VERSION ""

NS_ :

BS_:

BU_: Implement
VAL_TABLE_ Fault_Sig 1 "Fault" 0 "OK" ;
VAL_TABLE_ operation_mode 6 "Stop mode 2" 5 "Stop mode 1" 4 "Limited mode 4" 3 "Limited mode 3" 2 "Limited mode 2" 1 "Limited mode 1 " 0 "Normal Operation" ;

BO_ 3221225472 VECTOR__INDEPENDENT_SIG_MSG: 0 Vector__XXX
 SG_ New_Signal_80 : 0|8@1+ (1,0) [0|0] "" Vector__XXX
 SG_ New_Signal_78 : 0|8@1+ (1,0) [0|0] "" Vector__XXX
 SG_ _Bus_Input_Port_OutFaults : 0|16@0+ (1,0) [0|0] "" Vector__XXX
 SG_ MtrRpmFltrdDelay : 0|16@0- (1,0) [0|0] "" Vector__XXX
 SG_ MtrCrntFltrdDelay : 0|16@0- (1,0) [0|0] "" Vector__XXX
 SG_ Motor_rpm_sum : 0|16@0+ (1,0) [0|0] "RPM" Vector__XXX
 SG_ Cal_seq : 0|8@0+ (1,0) [0|0] "" Vector__XXX
 SG_ MtrRpmFltrdDelay : 0|16@0- (1,0) [0|0] "" Vector__XXX
 SG_ _Bus_Diag_Port_OD_MtrRpmFltrd : 0|16@0- (1,0) [0|0] "" Vector__XXX
 SG_ Operation_Mode : 0|8@0+ (1,0) [0|0] "" Vector__XXX
 SG_ MxDispRpmCapt : 0|16@0+ (1,0) [0|0] "" Vector__XXX
 SG_ _Bus_Diag_Port_OD_MtrFbCrntFltrd : 0|16@0- (1,0) [0|0] "" Vector__XXX
 SG_ TankLevel : 0|16@1+ (1,0) [0|10600] "L" Vector__XXX

BO_ 568 _Bus_Outputs_Braking_Abnormal: 8 Vector__XXX
 SG_ Press_Sensor_Plaus_Check : 15|8@0+ (1,0) [0|0] "" Vector__XXX
 SG_ Braking_Abnormal : 0|8@1+ (1,0) [0|0] "" Vector__XXX

BO_ 569 DanfossVersion: 8 Vector__XXX
 SG_ DanfossModuleVersion : 39|32@0+ (1,0) [0|0] "" Vector__XXX
 SG_ DanfossConfigVersion : 7|32@0+ (1,0) [0|0] "" Vector__XXX

BO_ 567 _Bus_Input_Port_OutFaults: 8 Vector__XXX
 SG_ _Bus_Input_Port_AggrMode_LvrAcc : 24|8@1- (1,0) [0|0] "" Vector__XXX
 SG_ _Bus_Input_Port_OperationMode : 23|8@0+ (1,0) [0|0] "" Vector__XXX
 SG_ PmpRvs_short_to_battery : 9|1@0+ (1,0) [0|0] "" Vector__XXX
 SG_ PmpFwd_short_to_battery : 8|1@0+ (1,0) [0|0] "" Vector__XXX
 SG_ ParkBrake_short_to_battery : 15|1@0+ (1,0) [0|0] "" Vector__XXX
 SG_ MtrCoilRR_coil_short_to_battery : 13|1@0+ (1,0) [0|0] "" Vector__XXX
 SG_ MtrCoilRL_coil_short_to_battery : 12|1@0+ (1,0) [0|0] "" Vector__XXX
 SG_ MtrCoilFR_coil_short_to_battery : 11|1@0+ (1,0) [0|0] "" Vector__XXX
 SG_ MtrCoilFL_coil_short_to_battery : 10|1@0+ (1,0) [0|0] "" Vector__XXX
 SG_ CCO_short_to_battery : 14|1@0+ (1,0) [0|0] "" Vector__XXX
 SG_ PmpRvs_coil_open_short_to_GND : 1|1@0+ (1,0) [0|0] "" Vector__XXX
 SG_ PmpFwd_coil_open_short_to_GND : 0|1@0+ (1,0) [0|0] "" Vector__XXX
 SG_ ParkBrake_open_short_to_GND : 7|1@0+ (1,0) [0|0] "" Vector__XXX
 SG_ MtrCoilRR_coil_open_short_to_GND : 5|1@0+ (1,0) [0|0] "" Vector__XXX
 SG_ MtrCoilRL_coil_open_short_to_GND : 4|1@0+ (1,0) [0|0] "" Vector__XXX
 SG_ MtrCoilFR_coil_open_short_to_GND : 3|1@0+ (1,0) [0|0] "" Vector__XXX
 SG_ MtrCoilFL_coil_open_short_to_GND : 2|1@0+ (1,0) [0|0] "" Vector__XXX
 SG_ CCO_open_short_to_GND : 6|1@0+ (1,0) [0|0] "" Vector__XXX

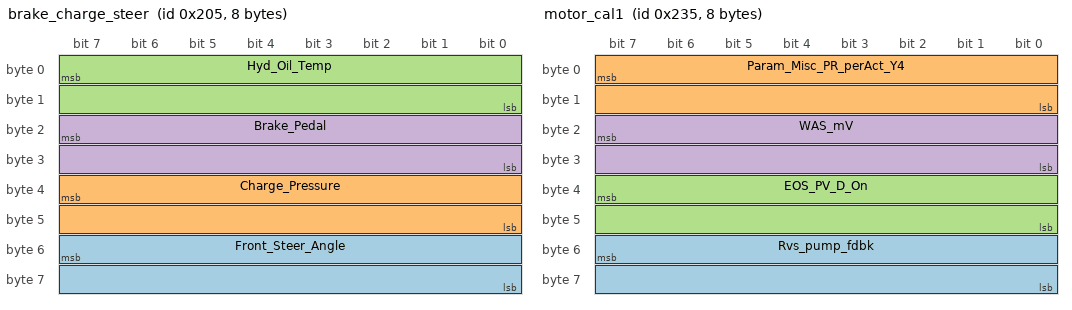
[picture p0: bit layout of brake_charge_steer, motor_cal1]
BO_ 517 brake_charge_steer: 8 Vector__XXX
 SG_ Front_Steer_Angle : 55|16@0- (0.01,0) [0|0] "deg" Vector__XXX
 SG_ Charge_Pressure : 39|16@0+ (1,0) [0|0] "" Vector__XXX
 SG_ Hyd_Oil_Temp : 7|16@0+ (1,0) [0|0] "c" Vector__XXX
 SG_ Brake_Pedal : 23|16@0+ (1,0) [0|0] "%" Vector__XXX

BO_ 565 motor_cal1: 8 Vector__XXX
 SG_ Rvs_pump_fdbk : 55|16@0+ (1,0) [0|0] "mA" Vector__XXX
 SG_ Param_Misc_PR_perAct_Y4 : 7|16@0+ (1,0) [0|0] "" Vector__XXX
 SG_ EOS_PV_D_On : 39|16@0+ (1,0) [0|0] "" Vector__XXX
 SG_ WAS_mV : 23|16@0+ (1,0) [0|0] "mV" Vector__XXX

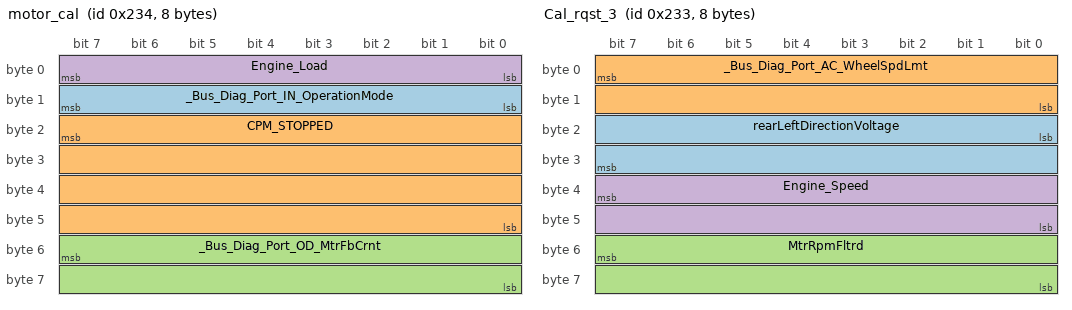
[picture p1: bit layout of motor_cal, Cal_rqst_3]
BO_ 564 motor_cal: 8 Vector__XXX
 SG_ _Bus_Diag_Port_IN_OperationMode : 8|8@1- (1,0) [0|0] "" Vector__XXX
 SG_ CPM_STOPPED : 23|32@0+ (1,0) [0|0] "" Vector__XXX
 SG_ _Bus_Diag_Port_OD_MtrFbCrnt : 55|16@0+ (1,0) [0|0] "" Vector__XXX
 SG_ Engine_Load : 7|8@0+ (1,0) [0|0] "%" Vector__XXX

BO_ 563 Cal_rqst_3: 8 Vector__XXX
 SG_ rearLeftDirectionVoltage : 16|16@1+ (1,0) [0|0] "V" Vector__XXX
 SG_ _Bus_Diag_Port_AC_WheelSpdLmt : 7|16@0+ (1,0) [0|0] "mmSec" Vector__XXX
 SG_ MtrRpmFltrd : 55|16@0- (1,0) [0|0] "" Vector__XXX
 SG_ Engine_Speed : 39|16@0+ (1,0) [0|0] "RPM" Vector__XXX

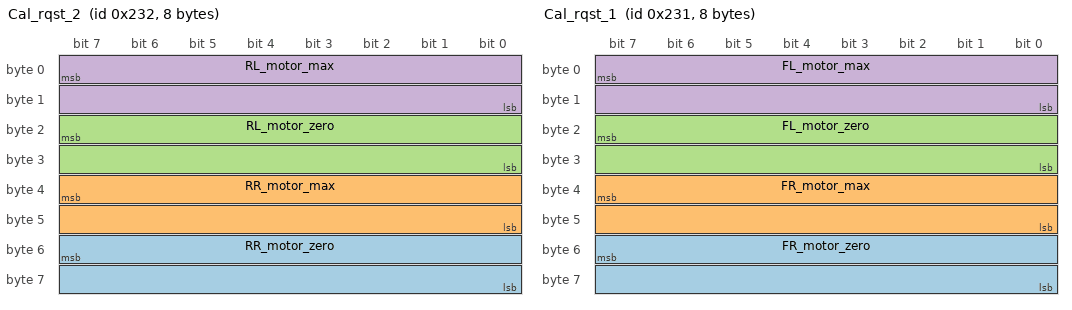
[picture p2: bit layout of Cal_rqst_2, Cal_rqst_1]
BO_ 562 Cal_rqst_2: 8 Vector__XXX
 SG_ RR_motor_zero : 55|16@0+ (1,0) [0|0] "mA" Vector__XXX
 SG_ RR_motor_max : 39|16@0+ (1,0) [0|0] "mA" Vector__XXX
 SG_ RL_motor_zero : 23|16@0+ (1,0) [0|0] "mA" Vector__XXX
 SG_ RL_motor_max : 7|16@0+ (1,0) [0|0] "mA" Vector__XXX

BO_ 561 Cal_rqst_1: 8 Vector__XXX
 SG_ FR_motor_zero : 55|16@0+ (1,0) [0|0] "mA" Vector__XXX
 SG_ FR_motor_max : 39|16@0+ (1,0) [0|0] "mA" Vector__XXX
 SG_ FL_motor_zero : 23|16@0+ (1,0) [0|0] "mA" Vector__XXX
 SG_ FL_motor_max : 7|16@0+ (1,0) [0|0] "mA" Vector__XXX

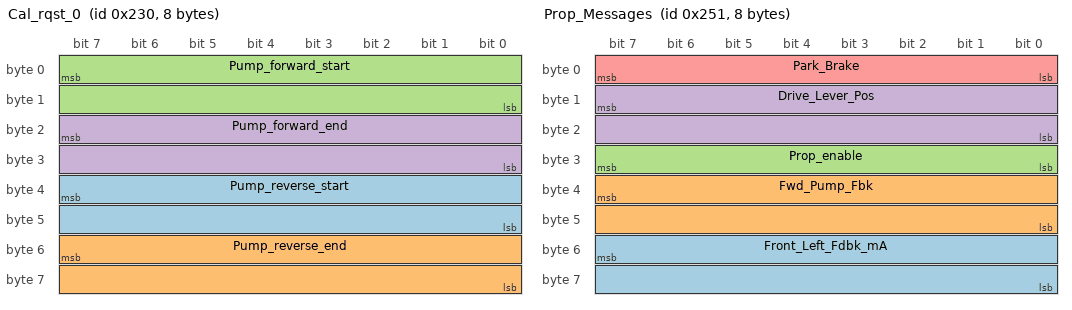
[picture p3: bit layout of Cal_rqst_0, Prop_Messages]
BO_ 560 Cal_rqst_0: 8 Vector__XXX
 SG_ Pump_reverse_start : 39|16@0+ (1,0) [0|0] "mA" Vector__XXX
 SG_ Pump_reverse_end : 55|16@0+ (1,0) [0|0] "mA" Vector__XXX
 SG_ Pump_forward_start : 7|16@0+ (1,0) [0|0] "mA" Vector__XXX
 SG_ Pump_forward_end : 23|16@0+ (1,0) [0|0] "mA" Vector__XXX

BO_ 593 Prop_Messages: 8 Vector__XXX
 SG_ Front_Left_Fdbk_mA : 55|16@0+ (1,0) [0|0] "mA" Vector__XXX
 SG_ Fwd_Pump_Fbk : 39|16@0+ (1,0) [0|0] "mA" Vector__XXX
 SG_ Prop_enable : 24|8@1- (1,0) [0|0] "" Vector__XXX
 SG_ Drive_Lever_Pos : 15|16@0- (1,0) [0|0] "%" Vector__XXX
 SG_ Park_Brake : 0|8@1- (1,0) [0|0] "" Vector__XXX

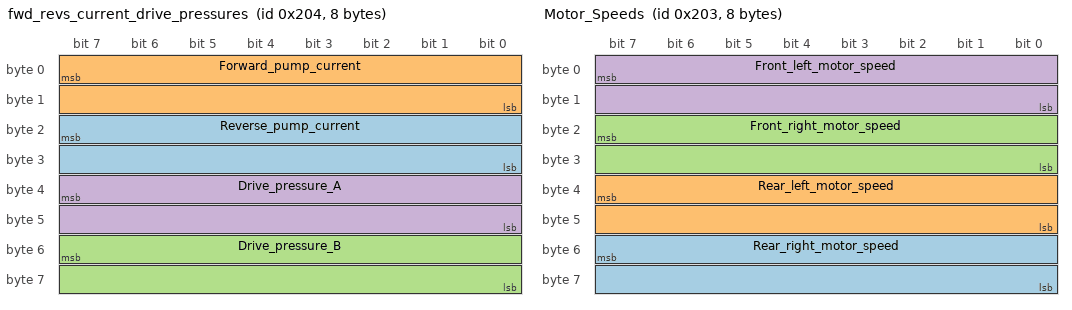
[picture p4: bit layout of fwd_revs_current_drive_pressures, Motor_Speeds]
BO_ 516 fwd_revs_current_drive_pressures: 8 Vector__XXX
 SG_ Reverse_pump_current : 23|16@0+ (1,0) [0|0] "Amps" Vector__XXX
 SG_ Forward_pump_current : 7|16@0+ (1,0) [0|0] "Amps" Vector__XXX
 SG_ Drive_pressure_B : 55|16@0+ (1,0) [0|0] "Bar" Vector__XXX
 SG_ Drive_pressure_A : 39|16@0+ (1,0) [0|0] "Bar" Vector__XXX

BO_ 515 Motor_Speeds: 8 Vector__XXX
 SG_ Rear_right_motor_speed : 55|16@0- (1,0) [0|0] "RPM" Vector__XXX
 SG_ Rear_left_motor_speed : 39|16@0- (1,0) [0|0] "RPM" Vector__XXX
 SG_ Front_right_motor_speed : 23|16@0- (1,0) [0|0] "RPM" Vector__XXX
 SG_ Front_left_motor_speed : 7|16@0- (1,0) [0|0] "RPM" Vector__XXX

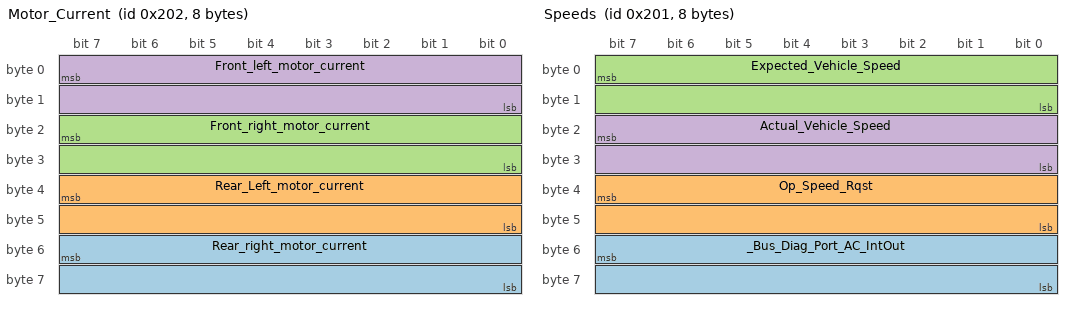
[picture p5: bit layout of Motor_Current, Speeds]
BO_ 514 Motor_Current: 8 Vector__XXX
 SG_ Rear_right_motor_current : 55|16@0+ (1,0) [0|0] "mA" Vector__XXX
 SG_ Rear_Left_motor_current : 39|16@0+ (1,0) [0|0] "mA" Vector__XXX
 SG_ Front_right_motor_current : 23|16@0+ (1,0) [0|0] "mA" Vector__XXX
 SG_ Front_left_motor_current : 7|16@0+ (1,0) [0|0] "mA" Vector__XXX

BO_ 513 Speeds: 8 Vector__XXX
 SG_ _Bus_Diag_Port_AC_IntOut : 55|16@0- (1,0) [0|0] "mm/s" Vector__XXX
 SG_ Op_Speed_Rqst : 39|16@0- (1,0) [0|0] "mm/s" Vector__XXX
 SG_ Expected_Vehicle_Speed : 7|16@0- (1,0) [0|0] "mm/s" Vector__XXX
 SG_ Actual_Vehicle_Speed : 23|16@0- (1,0) [0|0] "mm/s" Vector__XXX

CM_ BO_ 3221225472 "This is a message for not used signals, created by Vector CANdb++ DBC OLE DB Provider.";
BA_DEF_ SG_  "SigType" ENUM  "Default","Range","RangeSigned","ASCII","Discrete","Control","ReferencePGN","DTC","StringDelimiter","StringLength","StringLengthControl","MessageCounter","MessageChecksum";
BA_DEF_ SG_  "GenSigEVName" STRING ;
BA_DEF_ SG_  "GenSigILSupport" ENUM  "No","Yes";
BA_DEF_ SG_  "GenSigSendType" ENUM  "Cyclic","OnWrite","OnWriteWithRepetition","OnChange","OnChangeWithRepetition","IfActive","IfActiveWithRepetition","NoSigSendType";
BA_DEF_ BO_  "GenMsgILSupport" ENUM  "No","Yes";
BA_DEF_ BU_  "NmJ1939SystemInstance" INT 0 15;
BA_DEF_ BU_  "NmJ1939System" INT 0 127;
BA_DEF_ BU_  "NmJ1939ManufacturerCode" INT 0 2047;
BA_DEF_ BU_  "NmJ1939IndustryGroup" INT 0 7;
BA_DEF_ BU_  "NmJ1939IdentityNumber" INT 0 2097151;
BA_DEF_ BU_  "NmJ1939FunctionInstance" INT 0 7;
BA_DEF_ BU_  "NmJ1939Function" INT 0 255;
BA_DEF_ BU_  "NmJ1939ECUInstance" INT 0 3;
BA_DEF_ BU_  "NmJ1939AAC" INT 0 1;
BA_DEF_ BU_  "NmStationAddress" INT 0 255;
BA_DEF_ BO_  "GenMsgSendType" ENUM  "cyclic","NotUsed","IfActive","NotUsed","NotUsed","NotUsed","NotUsed","NotUsed","noMsgSendType";
BA_DEF_ BO_  "GenMsgRequestable" INT 0 1;
BA_DEF_  "DBName" STRING ;
BA_DEF_  "BusType" STRING ;
BA_DEF_  "ProtocolType" STRING ;
BA_DEF_ BO_  "VFrameFormat" ENUM  "StandardCAN","ExtendedCAN","reserved","J1939PG";
BA_DEF_DEF_  "SigType" "Default";
BA_DEF_DEF_  "GenSigEVName" "Env@Nodename_@Signame";
BA_DEF_DEF_  "GenSigILSupport" "Yes";
BA_DEF_DEF_  "GenSigSendType" "NoSigSendType";
BA_DEF_DEF_  "GenMsgILSupport" "Yes";
BA_DEF_DEF_  "NmJ1939SystemInstance" 0;
BA_DEF_DEF_  "NmJ1939System" 0;
BA_DEF_DEF_  "NmJ1939ManufacturerCode" 0;
BA_DEF_DEF_  "NmJ1939IndustryGroup" 0;
BA_DEF_DEF_  "NmJ1939IdentityNumber" 0;
BA_DEF_DEF_  "NmJ1939FunctionInstance" 0;
BA_DEF_DEF_  "NmJ1939Function" 0;
BA_DEF_DEF_  "NmJ1939ECUInstance" 0;
BA_DEF_DEF_  "NmJ1939AAC" 0;
BA_DEF_DEF_  "NmStationAddress" 254;
BA_DEF_DEF_  "GenMsgSendType" "noMsgSendType";
BA_DEF_DEF_  "GenMsgRequestable" 1;
BA_DEF_DEF_  "DBName" "";
BA_DEF_DEF_  "BusType" "CAN";
BA_DEF_DEF_  "ProtocolType" "J1939";
BA_DEF_DEF_  "VFrameFormat" "J1939PG";
BA_ "DBName" "RG3_Logger";
BA_ "NmJ1939IdentityNumber" BU_ Implement 965077;
BA_ "NmJ1939ManufacturerCode" BU_ Implement 102;
BA_ "NmJ1939ECUInstance" BU_ Implement 1;
BA_ "NmJ1939Function" BU_ Implement 132;
BA_ "NmJ1939System" BU_ Implement 6;
BA_ "NmJ1939IndustryGroup" BU_ Implement 2;
BA_ "NmJ1939AAC" BU_ Implement 1;
BA_ "NmStationAddress" BU_ Implement 128;
BA_ "VFrameFormat" BO_ 568 0;
BA_ "VFrameFormat" BO_ 569 0;
BA_ "VFrameFormat" BO_ 567 0;
BA_ "VFrameFormat" BO_ 517 0;
BA_ "VFrameFormat" BO_ 565 0;
BA_ "VFrameFormat" BO_ 564 0;
BA_ "VFrameFormat" BO_ 563 0;
BA_ "VFrameFormat" BO_ 562 0;
BA_ "VFrameFormat" BO_ 561 0;
BA_ "VFrameFormat" BO_ 560 0;
BA_ "VFrameFormat" BO_ 593 0;
BA_ "VFrameFormat" BO_ 516 0;
BA_ "VFrameFormat" BO_ 515 0;
BA_ "VFrameFormat" BO_ 514 0;
BA_ "VFrameFormat" BO_ 513 0;
VAL_ 3221225472 Operation_Mode 6 "Stop mode 2" 5 "Stop mode 1" 4 "Limited mode 4" 3 "Limited mode 3" 2 "Limited mode 2" 1 "Limited mode 1 " 0 "Normal Operation" ;
VAL_ 567 _Bus_Input_Port_OperationMode 64 "Stop Mode 2" 32 "Stop Mode 1" 16 "Limited Mode 4" 8 "Limited Mode 3" 4 "Limited Mode 2" 2 "Limited Mode 1" 1 "Normal Operation" 0 "Not Used" ;
VAL_ 567 PmpRvs_short_to_battery 1 "Fault" 0 "OK" ;
VAL_ 567 PmpFwd_short_to_battery 1 "Fault" 0 "OK" ;
VAL_ 567 ParkBrake_short_to_battery 1 "Fault" 0 "OK" ;
VAL_ 567 MtrCoilRR_coil_short_to_battery 1 "Fault" 0 "OK" ;
VAL_ 567 MtrCoilRL_coil_short_to_battery 1 "Fault" 0 "OK" ;
VAL_ 567 MtrCoilFR_coil_short_to_battery 1 "Fault" 0 "OK" ;
VAL_ 567 MtrCoilFL_coil_short_to_battery 1 "Fault" 0 "OK" ;
VAL_ 567 CCO_short_to_battery 1 "Fault" 0 "OK" ;
VAL_ 567 PmpRvs_coil_open_short_to_GND 1 "Fault" 0 "OK" ;
VAL_ 567 PmpFwd_coil_open_short_to_GND 1 "Fault" 0 "OK" ;
VAL_ 567 ParkBrake_open_short_to_GND 1 "Fault" 0 "OK" ;
VAL_ 567 MtrCoilRR_coil_open_short_to_GND 1 "Fault" 0 "OK" ;
VAL_ 567 MtrCoilRL_coil_open_short_to_GND 1 "Fault" 0 "OK" ;
VAL_ 567 MtrCoilFR_coil_open_short_to_GND 1 "Fault" 0 "OK" ;
VAL_ 567 MtrCoilFL_coil_open_short_to_GND 1 "Fault" 0 "OK" ;
VAL_ 567 CCO_open_short_to_GND 1 "Fault" 0 "OK" ;
